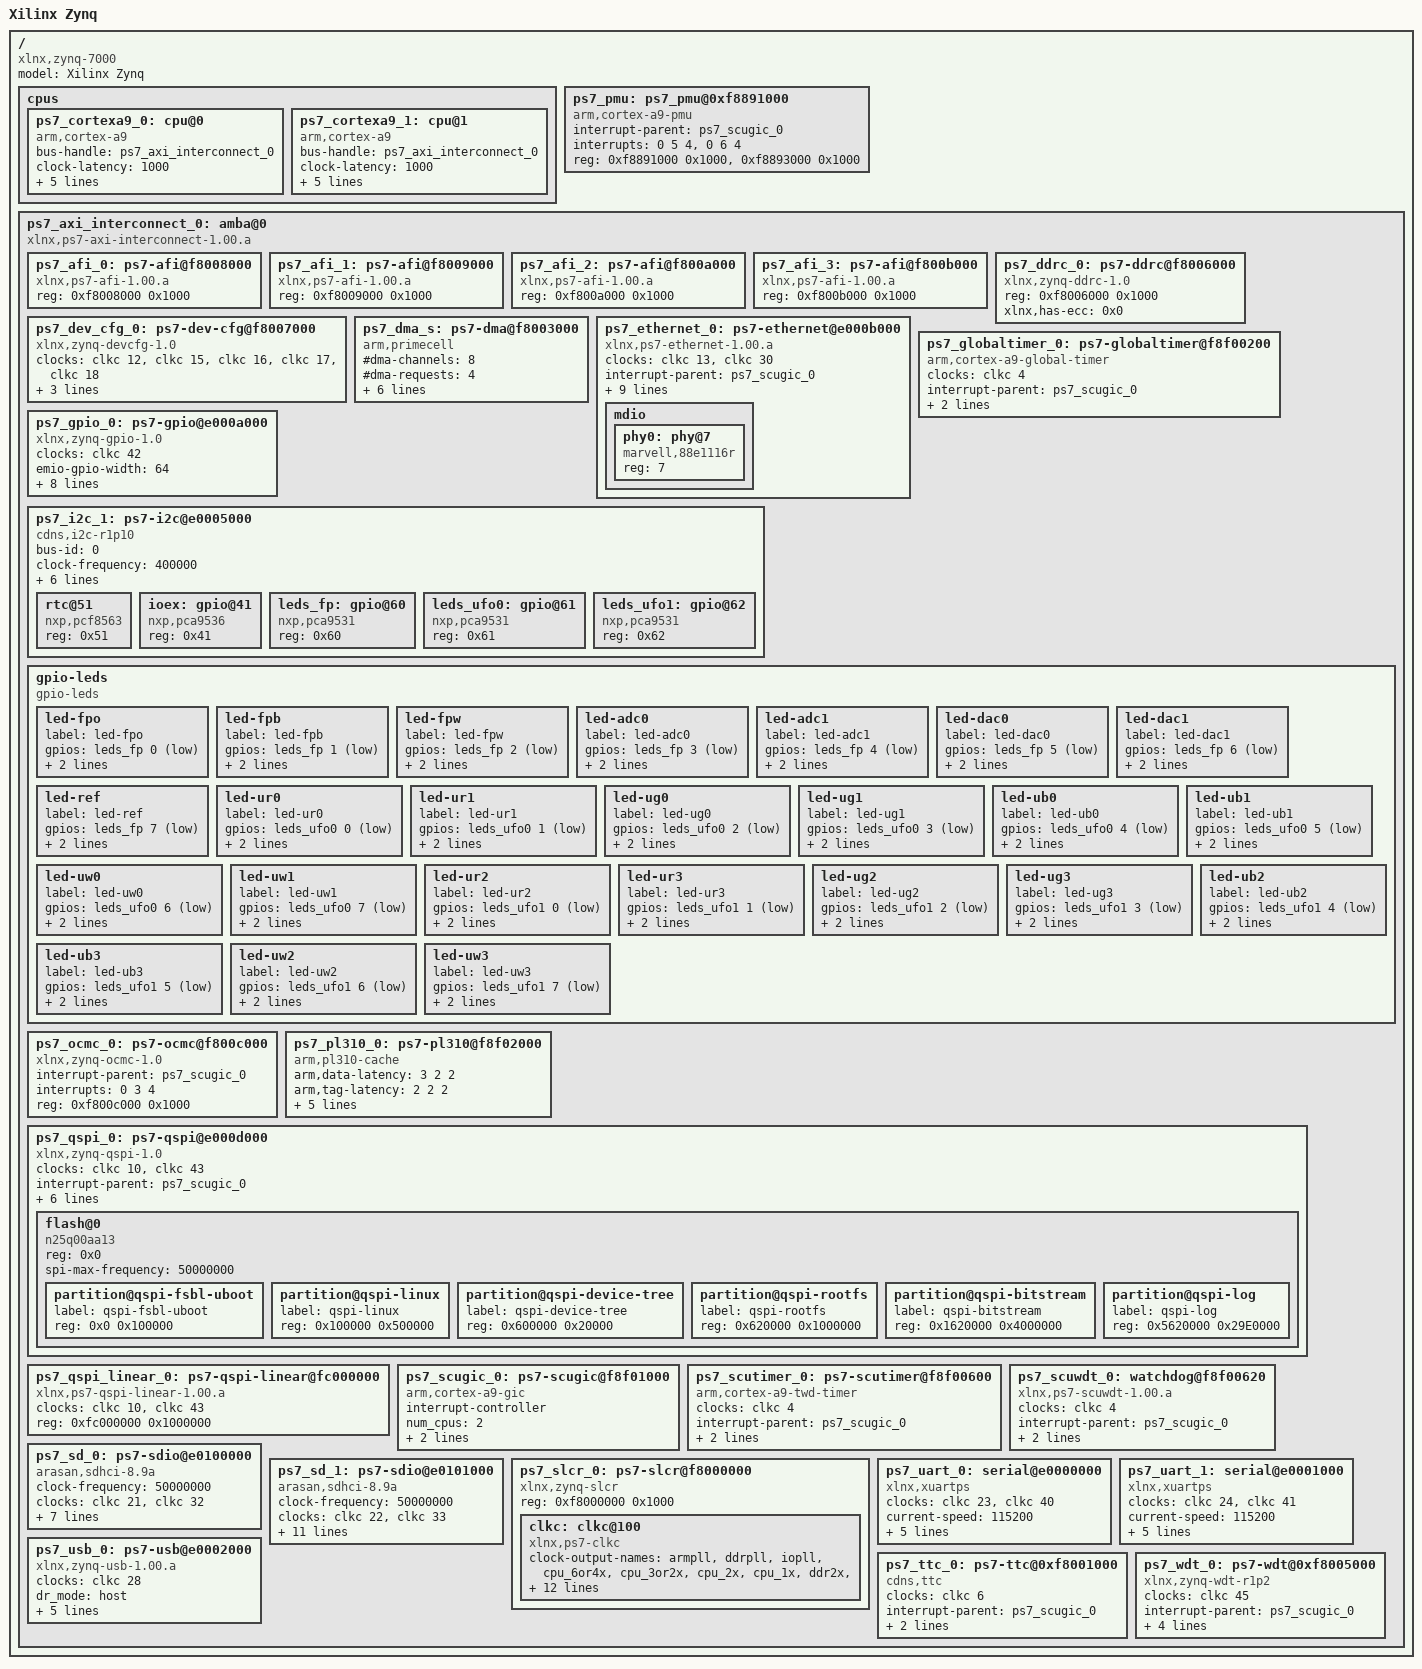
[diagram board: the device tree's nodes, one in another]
/*
 * CAUTION: This file is automatically generated by Xilinx.
 * Version:  
 * Today is: Wed Dec  3 15:57:26 2014
*/

/{
	#address-cells = <1>;
	#size-cells = <1>;
	compatible = "xlnx,zynq-7000";
	model = "Xilinx Zynq";
	cpus {
		#address-cells = <1>;
		#size-cells = <0>;
		ps7_cortexa9_0: cpu@0 {
			bus-handle = <&ps7_axi_interconnect_0>;
			clock-latency = <1000>;
			clocks = <&clkc 3>;
			compatible = "arm,cortex-a9";
			device_type = "cpu";
			interrupt-handle = <&ps7_scugic_0>;
			operating-points = <666667 1000000 333334 1000000 222223 1000000>;
			reg = <0x00>;
		} ;
		ps7_cortexa9_1: cpu@1 {
			bus-handle = <&ps7_axi_interconnect_0>;
			clock-latency = <1000>;
			clocks = <&clkc 3>;
			compatible = "arm,cortex-a9";
			device_type = "cpu";
			interrupt-handle = <&ps7_scugic_0>;
			operating-points = <666667 1000000 333334 1000000 222223 1000000>;
			reg = <0x01>;
		} ;
	} ;
	ps7_pmu: ps7_pmu@0xf8891000 {
		compatible = "arm,cortex-a9-pmu";
		interrupt-parent = <&ps7_scugic_0>;
		interrupts = <0 5 4>, <0 6 4>;
		reg = <0xf8891000 0x1000>, <0xf8893000 0x1000>;
		reg-names = "cpu0", "cpu1";
	} ;
	ps7_axi_interconnect_0: amba@0 {
		#address-cells = <1>;
		#size-cells = <1>;
		compatible = "xlnx,ps7-axi-interconnect-1.00.a", "simple-bus";
		ranges ;
		ps7_afi_0: ps7-afi@f8008000 {
			compatible = "xlnx,ps7-afi-1.00.a";
			reg = <0xf8008000 0x1000>;
		} ;
		ps7_afi_1: ps7-afi@f8009000 {
			compatible = "xlnx,ps7-afi-1.00.a";
			reg = <0xf8009000 0x1000>;
		} ;
		ps7_afi_2: ps7-afi@f800a000 {
			compatible = "xlnx,ps7-afi-1.00.a";
			reg = <0xf800a000 0x1000>;
		} ;
		ps7_afi_3: ps7-afi@f800b000 {
			compatible = "xlnx,ps7-afi-1.00.a";
			reg = <0xf800b000 0x1000>;
		} ;
		ps7_ddrc_0: ps7-ddrc@f8006000 {
			compatible = "xlnx,zynq-ddrc-1.0";
			reg = <0xf8006000 0x1000>;
			xlnx,has-ecc = <0x0>;
		} ;
		ps7_dev_cfg_0: ps7-dev-cfg@f8007000 {
			clock-names = "ref_clk", "fclk0", "fclk1", "fclk2", "fclk3";
			clocks = <&clkc 12>, <&clkc 15>, <&clkc 16>, <&clkc 17>, <&clkc 18>;
			compatible = "xlnx,zynq-devcfg-1.0";
			interrupt-parent = <&ps7_scugic_0>;
			interrupts = <0 8 4>;
			reg = <0xf8007000 0x100>;
		} ;
		ps7_dma_s: ps7-dma@f8003000 {
			#dma-cells = <1>;
			#dma-channels = <8>;
			#dma-requests = <4>;
			arm,primecell-periphid = <0x00041330>;
			clock-names = "apb_pclk";
			clocks = <&clkc 27>;
			compatible = "arm,primecell", "arm,pl330";
			interrupt-names = "abort", "dma0", "dma1", "dma2", "dma3", "dma4", "dma5", "dma6", "dma7";
			interrupt-parent = <&ps7_scugic_0>;
			interrupts = <0 13 4>, <0 14 4>, <0 15 4>, <0 16 4>, <0 17 4>, <0 40 4>, <0 41 4>, <0 42 4>, <0 43 4>;
			reg = <0xf8003000 0x1000>;
		} ;
		ps7_ethernet_0: ps7-ethernet@e000b000 {
			#address-cells = <1>;
			#size-cells = <0>;
			clock-names = "ref_clk", "aper_clk";
			clocks = <&clkc 13>, <&clkc 30>;
			compatible = "xlnx,ps7-ethernet-1.00.a";
			interrupt-parent = <&ps7_scugic_0>;
			interrupts = <0 22 4>;
			local-mac-address = [00 0a 35 00 00 00];
			phy-mode = "rgmii-id";
			phy-handle = <&phy0>;
			reg = <0xe000b000 0x1000>;
			xlnx,ptp-enet-clock = <0x69f6bcb>;
			xlnx,enet-reset = "";
			xlnx,eth-mode = <0x1>;
			xlnx,has-mdio = <0x1>;
			mdio {
				#address-cells = <1>;
				#size-cells = <0>;
				phy0: phy@7 {
					compatible = "marvell,88e1116r";
					device_type = "ethernet-phy";
					reg = <7>;
				} ;
			} ;
		} ;
		ps7_globaltimer_0: ps7-globaltimer@f8f00200 {
			clocks = <&clkc 4>;
			compatible = "arm,cortex-a9-global-timer";
			interrupt-parent = <&ps7_scugic_0>;
			interrupts = <1 11 0x301>;
			reg = <0xf8f00200 0x100>;
		} ;
		ps7_gpio_0: ps7-gpio@e000a000 {
			#gpio-cells = <2>;
			clocks = <&clkc 42>;
			compatible = "xlnx,zynq-gpio-1.0";
			emio-gpio-width = <64>;
			gpio-controller ;
			gpio-mask-high = <0x0>;
			gpio-mask-low = <0x5600>;
			interrupt-parent = <&ps7_scugic_0>;
			interrupts = <0 20 4>;
			reg = <0xe000a000 0x1000>;
			xlnx,emio-gpio-width = <0x40>;
			xlnx,mio-gpio-mask = <0x5600>;
		} ;
		ps7_i2c_1: ps7-i2c@e0005000 {
			#address-cells = <1>;
			#size-cells = <0>;
			bus-id = <0>;
			clock-frequency = <400000>;
			clocks = <&clkc 39>;
			compatible = "cdns,i2c-r1p10";
			interrupt-parent = <&ps7_scugic_0>;
			interrupts = <0 48 4>;
			reg = <0xe0005000 0x1000>;
			xlnx,has-interrupt = <0x1>;
			xlnx,i2c-reset = "<Select>";

			rtc@51 {
				compatible = "nxp,pcf8563";
				reg = <0x51>;
			};

			ioex: gpio@41 {
				compatible = "nxp,pca9536";
				reg = <0x41>;
			};

			leds_fp: gpio@60 {
				compatible = "nxp,pca9531";
				reg = <0x60>;
			};

			leds_ufo0: gpio@61 {
				compatible = "nxp,pca9531";
				reg = <0x61>;
			};

			leds_ufo1: gpio@62 {
				compatible = "nxp,pca9531";
				reg = <0x62>;
			};

			/* Apple Coprocessor at 0x10 accessed by userspace driver. */

		} ;
		gpio-leds {
			compatible = "gpio-leds";
			led-fpo {
				label = "led-fpo";
				gpios = <&leds_fp 0 1>;
				default-state = "off";
				linux,default-trigger = "heartbeat";
			};
			led-fpb {
				label = "led-fpb";
				gpios = <&leds_fp 1 1>;
				default-state = "off";
				linux,default-trigger = "heartbeat";
			};
			led-fpw {
				label = "led-fpw";
				gpios = <&leds_fp 2 1>;
				default-state = "off";
				linux,default-trigger = "heartbeat";
			};
			led-adc0 {
				label = "led-adc0";
				gpios = <&leds_fp 3 1>;
				default-state = "off";
				linux,default-trigger = "heartbeat";
			};
			led-adc1 {
				label = "led-adc1";
				gpios = <&leds_fp 4 1>;
				default-state = "off";
				linux,default-trigger = "heartbeat";
			};
			led-dac0 {
				label = "led-dac0";
				gpios = <&leds_fp 5 1>;
				default-state = "off";
				linux,default-trigger = "heartbeat";
			};
			led-dac1 {
				label = "led-dac1";
				gpios = <&leds_fp 6 1>;
				default-state = "off";
				linux,default-trigger = "heartbeat";
			};
			led-ref {
				label = "led-ref";
				gpios = <&leds_fp 7 1>;
				default-state = "off";
				linux,default-trigger = "heartbeat";
			};
			led-ur0 {
				label = "led-ur0";
				gpios = <&leds_ufo0 0 1>;
				default-state = "off";
				linux,default-trigger = "heartbeat";
			};
			led-ur1 {
				label = "led-ur1";
				gpios = <&leds_ufo0 1 1>;
				default-state = "off";
				linux,default-trigger = "heartbeat";
			};
			led-ug0 {
				label = "led-ug0";
				gpios = <&leds_ufo0 2 1>;
				default-state = "off";
				linux,default-trigger = "heartbeat";
			};
			led-ug1 {
				label = "led-ug1";
				gpios = <&leds_ufo0 3 1>;
				default-state = "off";
				linux,default-trigger = "heartbeat";
			};
			led-ub0 {
				label = "led-ub0";
				gpios = <&leds_ufo0 4 1>;
				default-state = "off";
				linux,default-trigger = "heartbeat";
			};
			led-ub1 {
				label = "led-ub1";
				gpios = <&leds_ufo0 5 1>;
				default-state = "off";
				linux,default-trigger = "heartbeat";
			};
			led-uw0 {
				label = "led-uw0";
				gpios = <&leds_ufo0 6 1>;
				default-state = "off";
				linux,default-trigger = "heartbeat";
			};
			led-uw1 {
				label = "led-uw1";
				gpios = <&leds_ufo0 7 1>;
				default-state = "off";
				linux,default-trigger = "heartbeat";
			};
			led-ur2 {
				label = "led-ur2";
				gpios = <&leds_ufo1 0 1>;
				default-state = "off";
				linux,default-trigger = "heartbeat";
			};
			led-ur3 {
				label = "led-ur3";
				gpios = <&leds_ufo1 1 1>;
				default-state = "off";
				linux,default-trigger = "heartbeat";
			};
			led-ug2 {
				label = "led-ug2";
				gpios = <&leds_ufo1 2 1>;
				default-state = "off";
				linux,default-trigger = "heartbeat";
			};
			led-ug3 {
				label = "led-ug3";
				gpios = <&leds_ufo1 3 1>;
				default-state = "off";
				linux,default-trigger = "heartbeat";
			};
			led-ub2 {
				label = "led-ub2";
				gpios = <&leds_ufo1 4 1>;
				default-state = "off";
				linux,default-trigger = "heartbeat";
			};
			led-ub3 {
				label = "led-ub3";
				gpios = <&leds_ufo1 5 1>;
				default-state = "off";
				linux,default-trigger = "heartbeat";
			};
			led-uw2 {
				label = "led-uw2";
				gpios = <&leds_ufo1 6 1>;
				default-state = "off";
				linux,default-trigger = "heartbeat";
			};
			led-uw3 {
				label = "led-uw3";
				gpios = <&leds_ufo1 7 1>;
				default-state = "off";
				linux,default-trigger = "heartbeat";
			};
		};
		ps7_ocmc_0: ps7-ocmc@f800c000 {
			compatible = "xlnx,zynq-ocmc-1.0";
			interrupt-parent = <&ps7_scugic_0>;
			interrupts = <0 3 4>;
			reg = <0xf800c000 0x1000>;
		} ;
		ps7_pl310_0: ps7-pl310@f8f02000 {
			arm,data-latency = <3 2 2>;
			arm,tag-latency = <2 2 2>;
			cache-level = <2>;
			cache-unified ;
			compatible = "arm,pl310-cache";
			interrupt-parent = <&ps7_scugic_0>;
			interrupts = <0 2 4>;
			reg = <0xf8f02000 0x1000>;
		} ;
		ps7_qspi_0: ps7-qspi@e000d000 {
			#address-cells = <1>;
			#size-cells = <0>;
			clock-names = "ref_clk", "aper_clk";
			clocks = <&clkc 10>, <&clkc 43>;
			compatible = "xlnx,zynq-qspi-1.0";
			interrupt-parent = <&ps7_scugic_0>;
			interrupts = <0 19 4>;
			is-dual = <0>;
			num-chip-select = <1>;
			reg = <0xe000d000 0x1000>;
			xlnx,fb-clk = <0x0>;
			xlnx,qspi-mode = <0x0>;

			flash@0 {
				compatible = "n25q00aa13";
				reg = <0x0>;
				spi-max-frequency = <50000000>;
				#address-cells = <1>;
				#size-cells = <1>;
				partition@qspi-fsbl-uboot {
					label = "qspi-fsbl-uboot";
					reg = <0x0 0x100000>;
				};
				partition@qspi-linux {
					label = "qspi-linux";
					reg = <0x100000 0x500000>;
				};
				partition@qspi-device-tree {
					label = "qspi-device-tree";
					reg = <0x600000 0x20000>;
				};
				partition@qspi-rootfs {
					label = "qspi-rootfs";
					reg = <0x620000 0x1000000>;
				};
				partition@qspi-bitstream {
					label = "qspi-bitstream";
					reg = <0x1620000 0x4000000>;
				};
				partition@qspi-log {
					label="qspi-log";
					reg = <0x5620000 0x29E0000>;
				};
			};
		} ;
		ps7_qspi_linear_0: ps7-qspi-linear@fc000000 {
			clock-names = "ref_clk", "aper_clk";
			clocks = <&clkc 10>, <&clkc 43>;
			compatible = "xlnx,ps7-qspi-linear-1.00.a";
			reg = <0xfc000000 0x1000000>;
		} ;
		ps7_scugic_0: ps7-scugic@f8f01000 {
			#address-cells = <2>;
			#interrupt-cells = <3>;
			#size-cells = <1>;
			compatible = "arm,cortex-a9-gic", "arm,gic";
			interrupt-controller ;
			num_cpus = <2>;
			num_interrupts = <96>;
			reg = <0xf8f01000 0x1000>, <0xf8f00100 0x100>;
		} ;
		ps7_scutimer_0: ps7-scutimer@f8f00600 {
			clocks = <&clkc 4>;
			compatible = "arm,cortex-a9-twd-timer";
			interrupt-parent = <&ps7_scugic_0>;
			interrupts = <1 13 0x301>;
			reg = <0xf8f00600 0x20>;
		} ;
		ps7_scuwdt_0: watchdog@f8f00620 {
			clocks = <&clkc 4>;
			compatible = "xlnx,ps7-scuwdt-1.00.a";
			device_type = "watchdog";
			interrupt-parent = <&ps7_scugic_0>;
			interrupts = <1 14 0x301>;
			reg = <0xf8f00620 0xe0>;
		} ;
		ps7_sd_0: ps7-sdio@e0100000 {
			clock-frequency = <50000000>;
			clock-names = "clk_xin", "clk_ahb";
			clocks = <&clkc 21>, <&clkc 32>;
			compatible = "arasan,sdhci-8.9a";
			interrupt-parent = <&ps7_scugic_0>;
			interrupts = <0 24 4>;
			reg = <0xe0100000 0x1000>;
			bus-width=<4>;
			xlnx,has-cd = <0x1>;
			xlnx,has-power = <0x0>;
			xlnx,has-wp = <0x1>;
		} ;
		ps7_sd_1: ps7-sdio@e0101000 {
			clock-frequency = <50000000>;
			clock-names = "clk_xin", "clk_ahb";
			clocks = <&clkc 22>, <&clkc 33>;
			compatible = "arasan,sdhci-8.9a";
			interrupt-parent = <&ps7_scugic_0>;
			interrupts = <0 47 4>;
			reg = <0xe0101000 0x1000>;
			xlnx,has-cd = <0x0>;
			xlnx,has-power = <0x0>;
			xlnx,has-wp = <0x0>;
			bus-width = <1>;
			non-removeable ;
			broken-cd ;
			cap-sdio-irq ;
			enable-sdio-wakeup ;
		} ;
		ps7_slcr_0: ps7-slcr@f8000000 {
			#address-cells = <1>;
			#size-cells = <1>;
			compatible = "xlnx,zynq-slcr", "syscon";
			ranges ;
			reg = <0xf8000000 0x1000>;
			clkc: clkc@100 {
				#clock-cells = <1>;
				clock-output-names = "armpll", "ddrpll", "iopll", "cpu_6or4x", "cpu_3or2x",
					"cpu_2x", "cpu_1x", "ddr2x", "ddr3x", "dci",
					"lqspi", "smc", "pcap", "gem0", "gem1",
					"fclk0", "fclk1", "fclk2", "fclk3", "can0",
					"can1", "sdio0", "sdio1", "uart0", "uart1",
					"spi0", "spi1", "dma", "usb0_aper", "usb1_aper",
					"gem0_aper", "gem1_aper", "sdio0_aper", "sdio1_aper", "spi0_aper",
					"spi1_aper", "can0_aper", "can1_aper", "i2c0_aper", "i2c1_aper",
					"uart0_aper", "uart1_aper", "gpio_aper", "lqspi_aper", "smc_aper",
					"swdt", "dbg_trc", "dbg_apb";
				compatible = "xlnx,ps7-clkc";
				fclk-enable = <0xf>;
				ps-clk-frequency = <33333333>;
				reg = <0x100 0x100>;
			} ;
		} ;
		ps7_uart_0: serial@e0000000 {
			clock-names = "uart_clk", "pclk";
			clocks = <&clkc 23>, <&clkc 40>;
			compatible = "xlnx,xuartps";
			current-speed = <115200>;
			device_type = "serial";
			interrupt-parent = <&ps7_scugic_0>;
			interrupts = <0 27 4>;
			port-number = <1>;
			reg = <0xe0000000 0x1000>;
			xlnx,has-modem = <0x0>;
		} ;
		ps7_uart_1: serial@e0001000 {
			clock-names = "uart_clk", "pclk";
			clocks = <&clkc 24>, <&clkc 41>;
			compatible = "xlnx,xuartps";
			current-speed = <115200>;
			device_type = "serial";
			interrupt-parent = <&ps7_scugic_0>;
			interrupts = <0 50 4>;
			port-number = <0>;
			reg = <0xe0001000 0x1000>;
			xlnx,has-modem = <0x0>;
		} ;
		ps7_usb_0: ps7-usb@e0002000 {
			clocks = <&clkc 28>;
			compatible = "xlnx,zynq-usb-1.00.a";
			dr_mode = "host";
			interrupt-parent = <&ps7_scugic_0>;
			interrupts = <0 21 4>;
			phy_type = "ulpi";
			reg = <0xe0002000 0x1000>;
			usb-reset = <&ps7_gpio_0 7 0>;
		} ;

		ps7_ttc_0: ps7-ttc@0xf8001000 {
			clocks = <&clkc 6>;
			compatible = "cdns,ttc";
			interrupt-names = "ttc0", "ttc1", "ttc2";
			interrupt-parent = <&ps7_scugic_0>;
			interrupts = <0 10 4>, <0 11 4>, <0 12 4>;
			reg = <0xF8001000 0x1000>;
		} ;
		ps7_wdt_0: ps7-wdt@0xf8005000 {
			clocks = <&clkc 45>;
			compatible = "xlnx,zynq-wdt-r1p2";
			device_type = "watchdog";
			interrupt-parent = <&ps7_scugic_0>;
			interrupts = <0 9 1>;
			reg = <0xF8005000 0x1000>;
			reset = <0>;
			timeout-sec = <10>;
		} ;
	} ;
} ;
